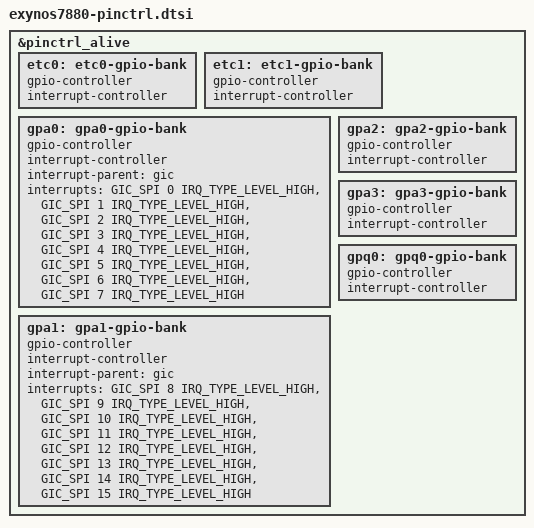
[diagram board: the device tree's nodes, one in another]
// SPDX-License-Identifier: GPL-2.0
/*
 * Samsung Exynos 7880 pin-mux and pin-config device tree source.
 *
 * Milestone 2: ALIVE controller only (keys). Bank layout and wake-up
 * interrupts from the Samsung universal7880 kernel:
 *   drivers/pinctrl/samsung/pinctrl-exynos.c exynos7880_pin_banks0
 *   arch/arm64/boot/dts/exynos7880.dtsi pinctrl_0 (SPI 0-15, SPI 16)
 */

#include <dt-bindings/interrupt-controller/arm-gic.h>
#include "exynos-pinctrl.h"

&pinctrl_alive {
	etc0: etc0-gpio-bank {
		gpio-controller;
		#gpio-cells = <2>;
		interrupt-controller;
		#interrupt-cells = <2>;
	};

	etc1: etc1-gpio-bank {
		gpio-controller;
		#gpio-cells = <2>;
		interrupt-controller;
		#interrupt-cells = <2>;
	};

	gpa0: gpa0-gpio-bank {
		gpio-controller;
		#gpio-cells = <2>;
		interrupt-controller;
		#interrupt-cells = <2>;
		interrupt-parent = <&gic>;
		interrupts = <GIC_SPI 0 IRQ_TYPE_LEVEL_HIGH>,
			     <GIC_SPI 1 IRQ_TYPE_LEVEL_HIGH>,
			     <GIC_SPI 2 IRQ_TYPE_LEVEL_HIGH>,
			     <GIC_SPI 3 IRQ_TYPE_LEVEL_HIGH>,
			     <GIC_SPI 4 IRQ_TYPE_LEVEL_HIGH>,
			     <GIC_SPI 5 IRQ_TYPE_LEVEL_HIGH>,
			     <GIC_SPI 6 IRQ_TYPE_LEVEL_HIGH>,
			     <GIC_SPI 7 IRQ_TYPE_LEVEL_HIGH>;
	};

	gpa1: gpa1-gpio-bank {
		gpio-controller;
		#gpio-cells = <2>;
		interrupt-controller;
		#interrupt-cells = <2>;
		interrupt-parent = <&gic>;
		interrupts = <GIC_SPI 8 IRQ_TYPE_LEVEL_HIGH>,
			     <GIC_SPI 9 IRQ_TYPE_LEVEL_HIGH>,
			     <GIC_SPI 10 IRQ_TYPE_LEVEL_HIGH>,
			     <GIC_SPI 11 IRQ_TYPE_LEVEL_HIGH>,
			     <GIC_SPI 12 IRQ_TYPE_LEVEL_HIGH>,
			     <GIC_SPI 13 IRQ_TYPE_LEVEL_HIGH>,
			     <GIC_SPI 14 IRQ_TYPE_LEVEL_HIGH>,
			     <GIC_SPI 15 IRQ_TYPE_LEVEL_HIGH>;
	};

	gpa2: gpa2-gpio-bank {
		gpio-controller;
		#gpio-cells = <2>;
		interrupt-controller;
		#interrupt-cells = <2>;
	};

	gpa3: gpa3-gpio-bank {
		gpio-controller;
		#gpio-cells = <2>;
		interrupt-controller;
		#interrupt-cells = <2>;
	};

	gpq0: gpq0-gpio-bank {
		gpio-controller;
		#gpio-cells = <2>;
		interrupt-controller;
		#interrupt-cells = <2>;
	};
};
